# HDSC_HC32M424 register map
Vendor: HDSC; Series: ARMCM4; File version: 1.0
CPU: CM4 r0p1, little endian, MPU, FPU, 4 interrupt priority bits
Registers are 32-bit, read-write, reset 0x0 unless marked. A register's access mark holds for its fields unless they carry their own. Offsets are from the block's base; [hi:lo] are bit positions; {n}, {i} and the like mark numbered series; 'fields as' and 'values as' point back to an identical list.

## ICG
Base 0x000002C0
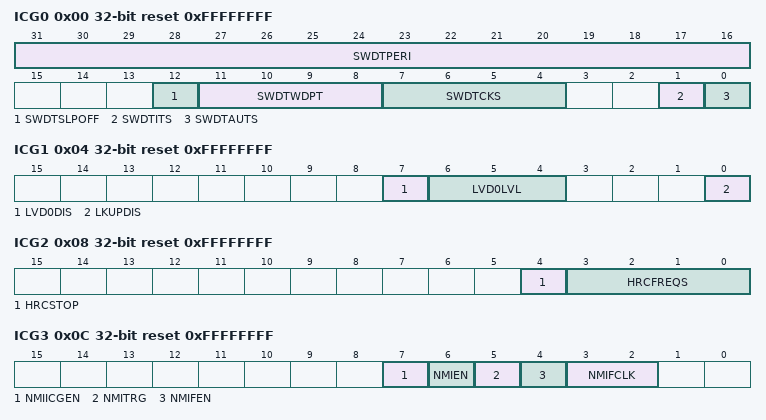
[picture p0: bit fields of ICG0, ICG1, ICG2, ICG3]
0x00 ICG0 ro reset 0xFFFFFFFF
  [31:16] SWDTPERI, [12] SWDTSLPOFF, [11:8] SWDTWDPT, [7:4] SWDTCKS, [1] SWDTITS, [0] SWDTAUTS
0x04 ICG1 ro reset 0xFFFFFFFF
  [7] LVD0DIS, [6:4] LVD0LVL, [0] LKUPDIS
0x08 ICG2 ro reset 0xFFFFFFFF
  [4] HRCSTOP rw, [3:0] HRCFREQS
0x0C ICG3 ro reset 0xFFFFFFFF
  [7] NMIICGEN, [6] NMIEN, [5] NMITRG, [4] NMIFEN, [3:2] NMIFCLK
{0x0+4i} ICG{i} ro reset 0xFFFFFFFF (reset mask 0x0) (i=4..9)

## PWC
Base 0x40054000
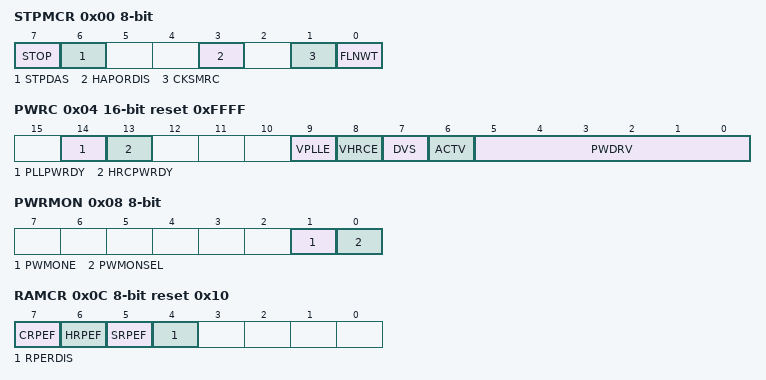
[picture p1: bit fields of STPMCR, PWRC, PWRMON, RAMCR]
0x00 STPMCR 8-bit
  [7] STOP, [6] STPDAS, [3] HAPORDIS, [1] CKSMRC, [0] FLNWT
0x04 PWRC 16-bit reset 0xFFFF
  [14] PLLPWRDY, [13] HRCPWRDY, [9] VPLLE, [8] VHRCE, [7] DVS, [6] ACTV, [5:0] PWDRV
0x08 PWRMON 8-bit
  [1] PWMONE, [0] PWMONSEL
0x0C RAMCR 8-bit reset 0x10
  [7] CRPEF, [6] HRPEF, [5] SRPEF, [4] RPERDIS
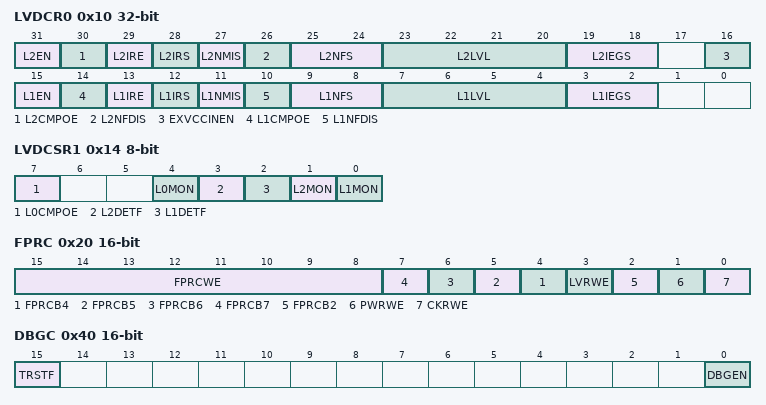
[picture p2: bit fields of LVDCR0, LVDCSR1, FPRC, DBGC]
0x10 LVDCR0
  [31] L2EN, [30] L2CMPOE, [29] L2IRE, [28] L2IRS, [27] L2NMIS, [26] L2NFDIS, [25:24] L2NFS, [23:20] L2LVL, [19:18] L2IEGS, [16] EXVCCINEN, [15] L1EN, [14] L1CMPOE, [13] L1IRE, [12] L1IRS, [11] L1NMIS, [10] L1NFDIS, [9:8] L1NFS, [7:4] L1LVL, [3:2] L1IEGS
0x14 LVDCSR1 8-bit
  [7] L0CMPOE, [4] L0MON, [3] L2DETF, [2] L1DETF, [1] L2MON ro, [0] L1MON ro
0x20 FPRC 16-bit
  [15:8] FPRCWE wo, [n] FPRCB{n} (n=4..7), [3] LVRWE, [2] FPRCB2, [1] PWRWE, [0] CKRWE
0x40 DBGC 16-bit
  [15] TRSTF, [0] DBGEN

## RMU
Base 0x40054100
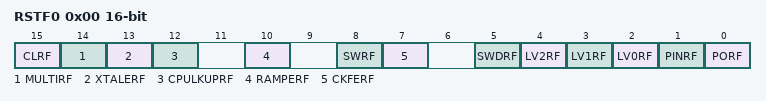
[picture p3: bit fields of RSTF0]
0x00 RSTF0 16-bit
  [15] CLRF, [14] MULTIRF, [13] XTALERF, [12] CPULKUPRF, [10] RAMPERF, [8] SWRF, [7] CKFERF, [5] SWDRF, [4] LV2RF, [3] LV1RF, [2] LV0RF, [1] PINRF, [0] PORF

## SPI
Base 0x4001C000
0x00 DR
  [15:0] SPD
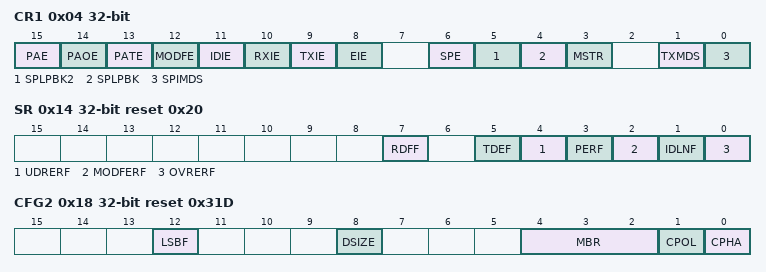
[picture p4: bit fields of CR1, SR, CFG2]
0x04 CR1
  [15] PAE, [14] PAOE, [13] PATE, [12] MODFE, [11] IDIE, [10] RXIE, [9] TXIE, [8] EIE, [6] SPE, [5] SPLPBK2, [4] SPLPBK, [3] MSTR, [1] TXMDS, [0] SPIMDS
0x0C CFG1 reset 0x10
  [8] SS0PV
0x14 SR reset 0x20
  [7] RDFF, [5] TDEF, [4] UDRERF, [3] PERF, [2] MODFERF, [1] IDLNF ro, [0] OVRERF
0x18 CFG2 reset 0x31D
  [12] LSBF, [8] DSIZE, [4:2] MBR, [1] CPOL, [0] CPHA

## SWDT
Base 0x40049400
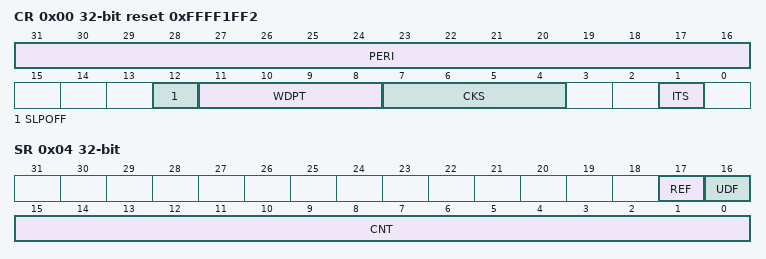
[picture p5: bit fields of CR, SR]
0x00 CR reset 0xFFFF1FF2
  [31:16] PERI, [12] SLPOFF, [11:8] WDPT, [7:4] CKS, [1] ITS
0x04 SR
  [17] REF, [16] UDF, [15:0] CNT ro
0x08 RR
  [15:0] RF

## TMR01 — desc TMR0
Base 0x40024000
Same registers: TMR02 0x40024400
0x00 CNTAR
  [15:0] CNTA
0x04 CNTBR
  [15:0] CNTB
0x08 CMPAR reset 0xFFFF
  [15:0] CMPA
0x0C CMPBR reset 0xFFFF
  [15:0] CMPB
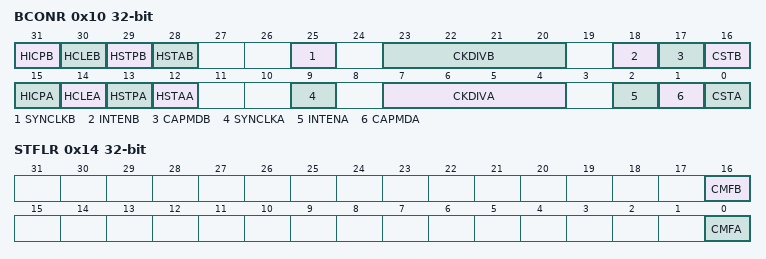
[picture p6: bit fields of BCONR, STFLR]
0x10 BCONR
  [31] HICPB, [30] HCLEB, [29] HSTPB, [28] HSTAB, [25] SYNCLKB, [23:20] CKDIVB, [18] INTENB, [17] CAPMDB, [16] CSTB, [15] HICPA, [14] HCLEA, [13] HSTPA, [12] HSTAA, [9] SYNCLKA, [7:4] CKDIVA, [2] INTENA, [1] CAPMDA, [0] CSTA
0x14 STFLR
  [16] CMFB, [0] CMFA

## TMR41 — desc TMR4
Base 0x40017000
Same registers: TMR42 0x40017400
0x00 OCCRUH 16-bit
0x04 OCCRUL 16-bit
0x08 OCCRVH 16-bit
0x0C OCCRVL 16-bit
0x10 OCCRWH 16-bit
0x14 OCCRWL 16-bit
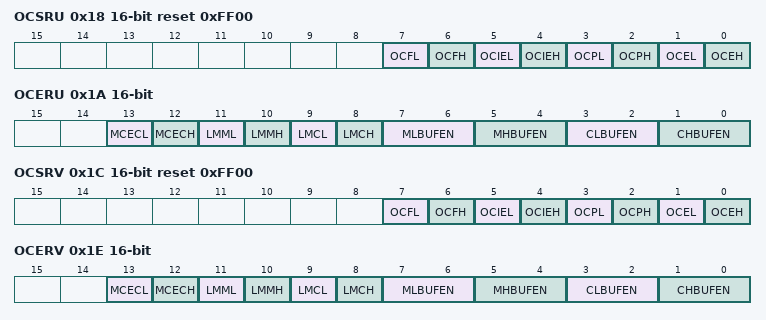
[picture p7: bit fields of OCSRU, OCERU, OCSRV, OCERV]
0x18 OCSRU 16-bit reset 0xFF00
  [7] OCFL, [6] OCFH, [5] OCIEL, [4] OCIEH, [3] OCPL, [2] OCPH, [1] OCEL, [0] OCEH
0x1A OCERU 16-bit
  [13] MCECL, [12] MCECH, [11] LMML, [10] LMMH, [9] LMCL, [8] LMCH, [7:6] MLBUFEN, [5:4] MHBUFEN, [3:2] CLBUFEN, [1:0] CHBUFEN
0x1C OCSRV 16-bit reset 0xFF00
  fields as OCSRU
0x1E OCERV 16-bit
  fields as OCERU
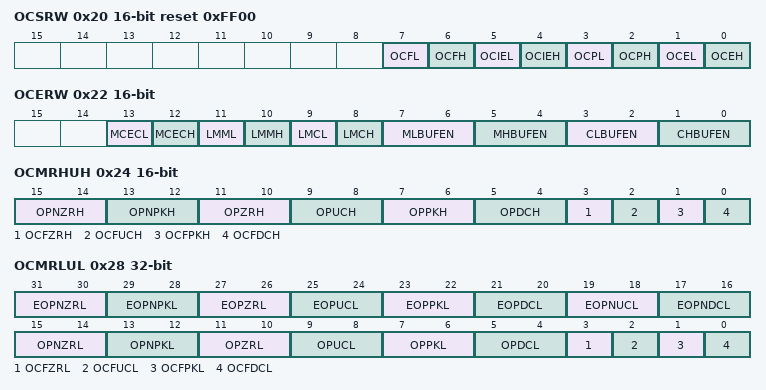
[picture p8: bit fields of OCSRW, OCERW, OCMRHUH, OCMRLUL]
0x20 OCSRW 16-bit reset 0xFF00
  fields as OCSRU
0x22 OCERW 16-bit
  fields as OCERU
0x24 OCMRHUH 16-bit
  [15:14] OPNZRH, [13:12] OPNPKH, [11:10] OPZRH, [9:8] OPUCH, [7:6] OPPKH, [5:4] OPDCH, [3] OCFZRH, [2] OCFUCH, [1] OCFPKH, [0] OCFDCH
0x28 OCMRLUL
  [31:30] EOPNZRL, [29:28] EOPNPKL, [27:26] EOPZRL, [25:24] EOPUCL, [23:22] EOPPKL, [21:20] EOPDCL, [19:18] EOPNUCL, [17:16] EOPNDCL, [15:14] OPNZRL, [13:12] OPNPKL, [11:10] OPZRL, [9:8] OPUCL, [7:6] OPPKL, [5:4] OPDCL, [3] OCFZRL, [2] OCFUCL, [1] OCFPKL, [0] OCFDCL
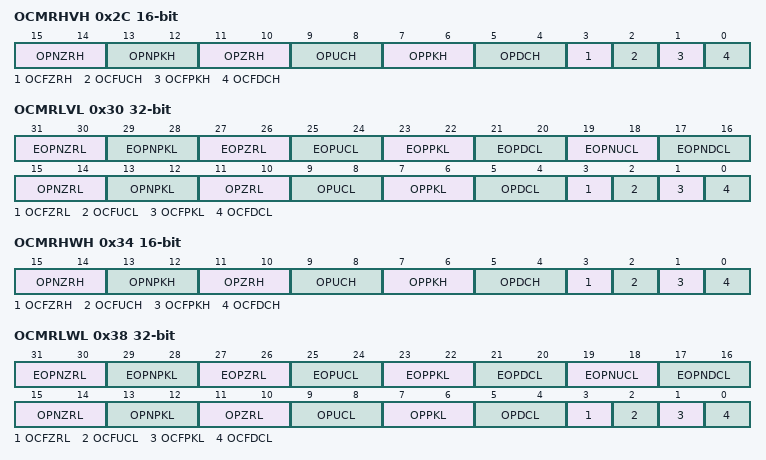
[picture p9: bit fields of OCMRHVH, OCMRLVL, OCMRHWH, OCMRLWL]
0x2C OCMRHVH 16-bit
  fields as OCMRHUH
0x30 OCMRLVL
  fields as OCMRLUL
0x34 OCMRHWH 16-bit
  fields as OCMRHUH
0x38 OCMRLWL
  fields as OCMRLUL
0x40 CPSR 16-bit reset 0xFFFF
0x44 CNTR 16-bit
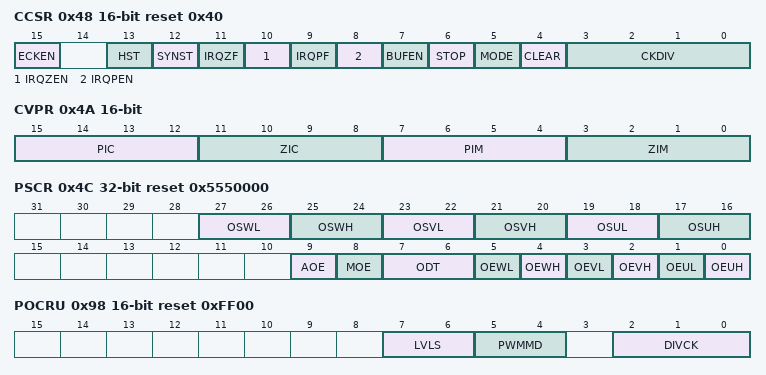
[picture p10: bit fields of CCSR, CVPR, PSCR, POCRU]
0x48 CCSR 16-bit reset 0x40
  [15] ECKEN, [13] HST, [12] SYNST, [11] IRQZF, [10] IRQZEN, [9] IRQPF, [8] IRQPEN, [7] BUFEN, [6] STOP, [5] MODE, [4] CLEAR, [3:0] CKDIV
0x4A CVPR 16-bit
  [15:12] PIC ro, [11:8] ZIC ro, [7:4] PIM, [3:0] ZIM
0x4C PSCR reset 0x5550000
  [27:26] OSWL, [25:24] OSWH, [23:22] OSVL, [21:20] OSVH, [19:18] OSUL, [17:16] OSUH, [9] AOE, [8] MOE, [7:6] ODT, [5] OEWL, [4] OEWH, [3] OEVL, [2] OEVH, [1] OEUL, [0] OEUH
0x82 PFSRU 16-bit
0x84 PDARU 16-bit
0x86 PDBRU 16-bit
0x8A PFSRV 16-bit
0x8C PDARV 16-bit
0x8E PDBRV 16-bit
0x92 PFSRW 16-bit
0x94 PDARW 16-bit
0x96 PDBRW 16-bit
0x98 POCRU 16-bit reset 0xFF00
  [7:6] LVLS, [5:4] PWMMD, [2:0] DIVCK
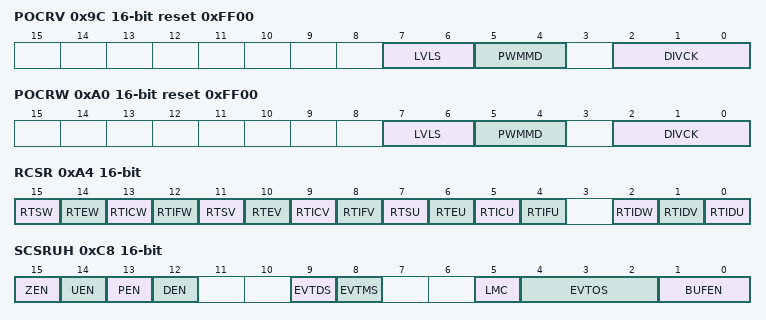
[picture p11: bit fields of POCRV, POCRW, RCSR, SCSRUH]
0x9C POCRV 16-bit reset 0xFF00
  [7:6] LVLS, [5:4] PWMMD, [2:0] DIVCK
0xA0 POCRW 16-bit reset 0xFF00
  [7:6] LVLS, [5:4] PWMMD, [2:0] DIVCK
0xA4 RCSR 16-bit
  [15] RTSW, [14] RTEW, [13] RTICW, [12] RTIFW ro, [11] RTSV, [10] RTEV, [9] RTICV, [8] RTIFV ro, [7] RTSU, [6] RTEU, [5] RTICU, [4] RTIFU ro, [2] RTIDW, [1] RTIDV, [0] RTIDU
0xB0 SCCRUH 16-bit
0xB4 SCCRUL 16-bit
0xB8 SCCRVH 16-bit
0xBC SCCRVL 16-bit
0xC0 SCCRWH 16-bit
0xC4 SCCRWL 16-bit
0xC8 SCSRUH 16-bit
  [15] ZEN, [14] UEN, [13] PEN, [12] DEN, [9] EVTDS, [8] EVTMS, [5] LMC, [4:2] EVTOS, [1:0] BUFEN
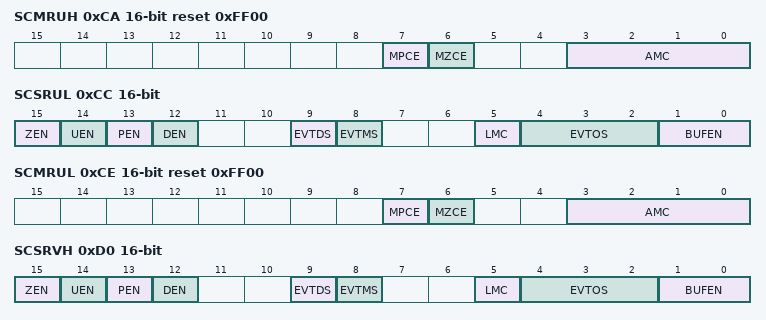
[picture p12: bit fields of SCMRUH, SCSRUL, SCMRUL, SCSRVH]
0xCA SCMRUH 16-bit reset 0xFF00
  [7] MPCE, [6] MZCE, [3:0] AMC
0xCC SCSRUL 16-bit
  fields as SCSRUH
0xCE SCMRUL 16-bit reset 0xFF00
  [7] MPCE, [6] MZCE, [3:0] AMC
0xD0 SCSRVH 16-bit
  fields as SCSRUH
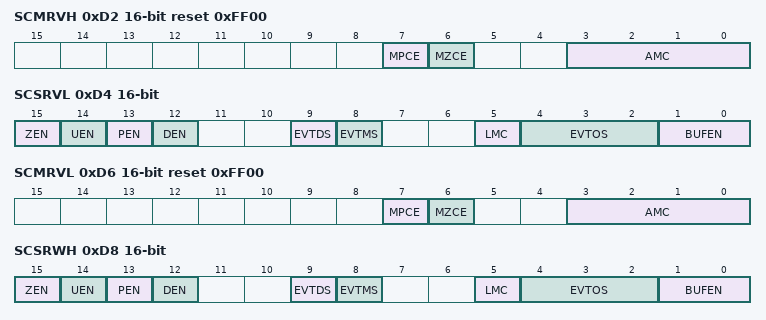
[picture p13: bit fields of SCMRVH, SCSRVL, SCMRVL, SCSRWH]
0xD2 SCMRVH 16-bit reset 0xFF00
  [7] MPCE, [6] MZCE, [3:0] AMC
0xD4 SCSRVL 16-bit
  fields as SCSRUH
0xD6 SCMRVL 16-bit reset 0xFF00
  [7] MPCE, [6] MZCE, [3:0] AMC
0xD8 SCSRWH 16-bit
  fields as SCSRUH
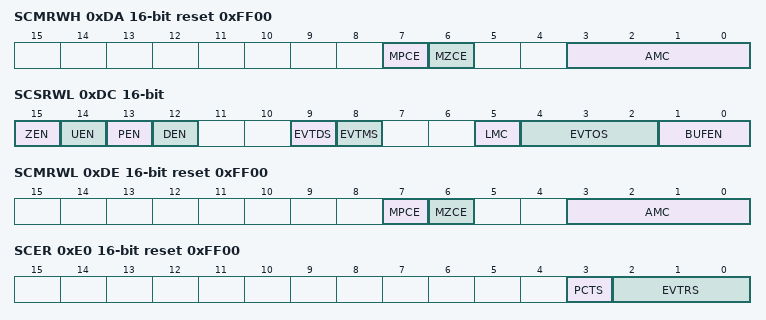
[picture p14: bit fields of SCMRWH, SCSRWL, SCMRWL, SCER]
0xDA SCMRWH 16-bit reset 0xFF00
  [7] MPCE, [6] MZCE, [3:0] AMC
0xDC SCSRWL 16-bit
  fields as SCSRUH
0xDE SCMRWL 16-bit reset 0xFF00
  [7] MPCE, [6] MZCE, [3:0] AMC
0xE0 SCER 16-bit reset 0xFF00
  [3] PCTS, [2:0] EVTRS

## TMRA1 — desc TMRA
Base 0x40015000
Same registers: TMRA2 0x40015400, TMRA3 0x40015800, TMRA4 0x40015C00, TMRA5 0x40016000, TMRA6 0x40016400
0x00 CNTER 16-bit
  [15:0] CNT
0x04 PERAR 16-bit reset 0xFFFF
  [15:0] PER
0x40 CMPAR1 16-bit reset 0xFFFF
  [15:0] CMP
0x44 CMPAR2 16-bit reset 0xFFFF
  [15:0] CMP
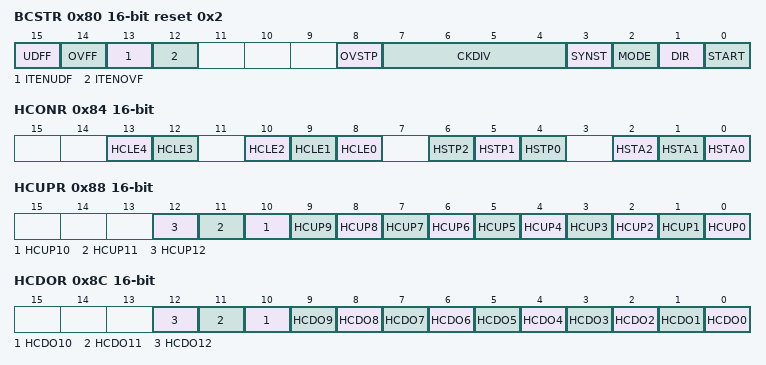
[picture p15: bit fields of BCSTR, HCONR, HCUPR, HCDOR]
0x80 BCSTR 16-bit reset 0x2
  [15] UDFF, [14] OVFF, [13] ITENUDF, [12] ITENOVF, [8] OVSTP, [7:4] CKDIV, [3] SYNST, [2] MODE, [1] DIR, [0] START
0x84 HCONR 16-bit
  [13] HCLE4, [12] HCLE3, [10] HCLE2, [9] HCLE1, [8] HCLE0, [6] HSTP2, [5] HSTP1, [4] HSTP0, [2] HSTA2, [1] HSTA1, [0] HSTA0
0x88 HCUPR 16-bit
  [n] HCUP{n} (n=0..12)
0x8C HCDOR 16-bit
  [n] HCDO{n} (n=0..12)
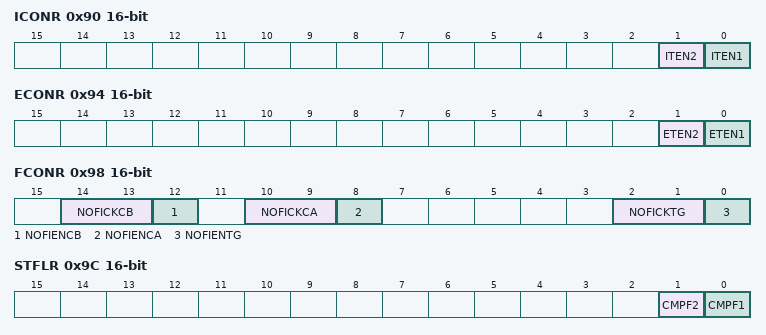
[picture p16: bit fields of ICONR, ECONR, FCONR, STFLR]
0x90 ICONR 16-bit
  [1] ITEN2, [0] ITEN1
0x94 ECONR 16-bit
  [1] ETEN2, [0] ETEN1
0x98 FCONR 16-bit
  [14:13] NOFICKCB, [12] NOFIENCB, [10:9] NOFICKCA, [8] NOFIENCA, [2:1] NOFICKTG, [0] NOFIENTG
0x9C STFLR 16-bit
  [1] CMPF2, [0] CMPF1
0xC0 BCONR 16-bit
  [2] BSE1, [1] BSE0, [0] BEN
0x100 CCONR1 16-bit
  [14:13] NOFICKCP, [12] NOFIENCP, [6] HICP2, [5] HICP1, [4] HICP0, [0] CAPMD
0x104 CCONR2 16-bit
  fields as CCONR1
0x140 PCONR1 16-bit
  [12] OUTEN, [9:8] FORC, [7:6] PERC, [5:4] CMPC, [3:2] STPC, [1:0] STAC
0x144 PCONR2 16-bit
  fields as PCONR1

## TMRB1 — desc TMRB
Base 0x40025000
Same registers: TMRB2 0x40025400, TMRB3 0x40025800
0x00 CNTER 16-bit
  [15:0] CNT
0x04 PERAR 16-bit reset 0xFFFF
  [15:0] PER
{0x3C+4i} CMPAR{i} 16-bit reset 0xFFFF (i=1..4)
  [15:0] CMP
0x80 BCSTR 16-bit reset 0x2
  [15] UDFF, [14] OVFF, [13] ITENUDF, [12] ITENOVF, [8] OVSTP, [7:4] CKDIV, [2] MODE, [1] DIR, [0] START
0x84 HCONR 16-bit
  [n+9] HCLE{n} (n=3..6), [10] HCLE2, [9] HCLE1, [8] HCLE0, [6] HSTP2, [5] HSTP1, [4] HSTP0, [2] HSTA2, [1] HSTA1, [0] HSTA0
0x88 HCUPR 16-bit
  [10] HCUP10, [9] HCUP9, [8] HCUP8
0x8C HCDOR 16-bit
  [10] HCDO10, [9] HCDO9, [8] HCDO8
0x90 ICONR 16-bit
  [n-1] ITEN{n} (n=1..4)
0x94 ECONR 16-bit
  [n-1] ETEN{n} (n=1..4)
0x9C STFLR 16-bit
  [n-1] CMPF{n} (n=1..4)
0xC0 BCONR1 16-bit
  [2] BSE1, [1] BSE0, [0] BEN
0xC8 BCONR2 16-bit
  [2] BSE1, [1] BSE0, [0] BEN
{0xFC+4i} CCONR{i} 16-bit (i=1..4)
  [14:13] NOFICKCP, [12] NOFIENCP, [6] HICP2, [5] HICP1, [4] HICP0, [0] CAPMD
{0x13C+4i} PCONR{i} 16-bit (i=1..4)
  [12] OUTEN, [9:8] FORC, [7:6] PERC, [5:4] CMPC, [3:2] STPC, [1:0] STAC

## USART1 — desc USART
Base 0x4001D000
Same registers: USART2 0x4001D400, USART3 0x40021000, USART4 0x40021400
0x00 SR ro reset 0xC0
  [16] MPB, [7] TXE, [6] TC, [5] RXNE, [3] ORE, [1] FE, [0] PE
0x04 DR reset 0x1FF
  [24:16] RDR, [9] MPID, [8:0] TDR
0x08 BRR reset 0xFF00
  [15:8] DIV_INTEGER
0x0C CR1 reset 0x80000000
  [31] SBS, [30] NFE, [28] ML, [24] MS, [19] CORE wo, [17] CFE wo, [16] CPE wo, [15] OVER8, [12] M, [10] PCE, [9] PS, [7] TXEIE, [6] TCIE, [5] RIE, [4] SLME, [3] TE, [2] RE
0x10 CR2
  [13] STOP, [12:11] CLKC, [0] MPE
0x14 CR3
  [9] CTSE, [8] RTSE, [3] HDSEL
0x18 PR
  [3:0] PSC
